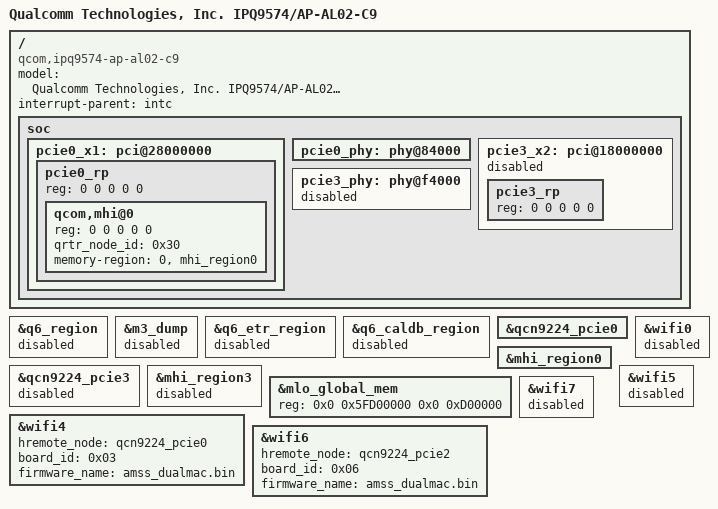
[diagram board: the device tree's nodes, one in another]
// SPDX-License-Identifier: (GPL-2.0+ OR BSD-3-Clause)
/*
 * IPQ9574 AL02-C9 board device tree source
 *
 * Copyright (c) 2020-2021 The Linux Foundation. All rights reserved.
 * Copyright (c) 2022 Qualcomm Innovation Center, Inc. All rights reserved.
 */

/dts-v1/;

#include "ipq9574-al02-c6.dts"

/ {
	#address-cells = <0x2>;
	#size-cells = <0x2>;
	model = "Qualcomm Technologies, Inc. IPQ9574/AP-AL02-C9";
	compatible = "qcom,ipq9574-ap-al02-c9", "qcom,ipq9574-al02", "qcom,ipq9574";
	interrupt-parent = <&intc>;

	soc {
		pcie0_x1: pci@28000000 {
			status = "ok";
			pcie0_rp {
				reg = <0 0 0 0 0>;

				qcom,mhi@0 {
					reg = <0 0 0 0 0>;
					qrtr_node_id = <0x30>;
					memory-region = <0>,<&mhi_region0>;
				};
			};
		};

		pcie0_phy: phy@84000 {
			status = "ok";
		};

		pcie3_x2: pci@18000000 {
			status = "disabled";
			/delete-node/ pcie3_rp;
			pcie3_rp {
				reg = <0 0 0 0 0>;
			};
		};

		pcie3_phy: phy@f4000 {
			status = "disabled";
		};
	};
};

/* Disable IPQ9574 integrated radio's reserved memory */
&q6_region {
	status = "disabled";
};

&m3_dump {
	status = "disabled";
};

&q6_etr_region {
	status = "disabled";
};

&q6_caldb_region {
	status = "disabled";
};

&qcn9224_pcie0 {
	status = "ok";
};

&mhi_region0 {
	status = "ok";
};

&qcn9224_pcie3 {
	status = "disabled";
};

&mhi_region3 {
	status = "disabled";
};

/* MLO GLOBAL MEM REGION size is 13MB for RDP with 2 QCN224 radios */
&mlo_global_mem {
	reg = <0x0 0x5FD00000 0x0 0xD00000>;
	status = "ok";
};

&wifi0 {
	/* Disable IPQ9574 integratd 2G Radio */
	status = "disabled";
};

&wifi4 {
	/* QCN9224 split-radio 2.4G + 5G */
	hremote_node = <&qcn9224_pcie0>;
	board_id = <0x03>;
	firmware_name = "amss_dualmac.bin";
	status = "ok";
};

&wifi5 {
	status = "disabled";
};

&wifi6 {
	/* QCN9224 split-radio 5G + 6G */
	hremote_node = <&qcn9224_pcie2>;
	board_id = <0x06>;
	firmware_name = "amss_dualmac.bin";
	status = "ok";
};

&wifi7 {
	status = "disabled";
};
